# ESP32-C61 register map
Vendor: ESPRESSIF SYSTEMS (SHANGHAI) CO., LTD.; Series: ESP32 C-Series; File version: 1
CPU: RV32IMAC r0p0, little endian, no MPU, no FPU, 0 interrupt priority bits
Address unit: 32 bits
Registers are 32-bit, read-write, reset 0x0 unless marked. A register's access mark holds for its fields unless they carry their own. Offsets are from the block's base; [hi:lo] are bit positions; {n}, {i} and the like mark numbered series.

## INTERRUPT_CORE0 — Interrupt Controller (Core 0)
Base 0x60010000
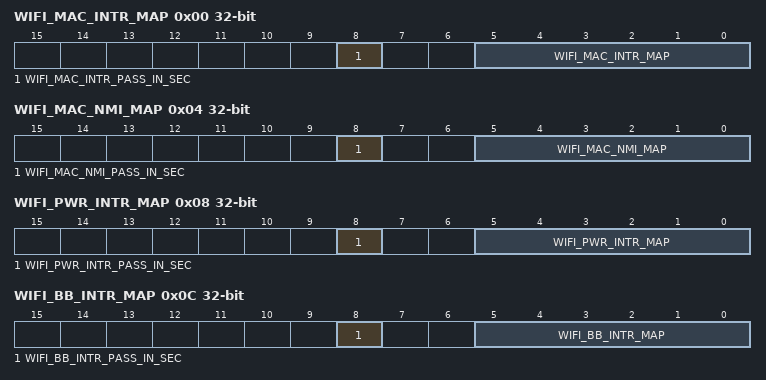
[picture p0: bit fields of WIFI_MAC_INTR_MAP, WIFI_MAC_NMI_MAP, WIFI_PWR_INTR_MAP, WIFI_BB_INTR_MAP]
0x00 WIFI_MAC_INTR_MAP — WIFI_MAC_INTR mapping register
  [8] WIFI_MAC_INTR_PASS_IN_SEC — Configures the PASS_IN_SEC flag of the interrupt source.
  [5:0] WIFI_MAC_INTR_MAP — Configures the interrupt source into one CPU interrupt.
0x04 WIFI_MAC_NMI_MAP — WIFI_MAC_NMI mapping register
  [8] WIFI_MAC_NMI_PASS_IN_SEC — Configures the PASS_IN_SEC flag of the interrupt source.
  [5:0] WIFI_MAC_NMI_MAP — Configures the interrupt source into one CPU interrupt.
0x08 WIFI_PWR_INTR_MAP — WIFI_PWR_INTR mapping register
  [8] WIFI_PWR_INTR_PASS_IN_SEC — Configures the PASS_IN_SEC flag of the interrupt source.
  [5:0] WIFI_PWR_INTR_MAP — Configures the interrupt source into one CPU interrupt.
0x0C WIFI_BB_INTR_MAP — WIFI_BB_INTR mapping register
  [8] WIFI_BB_INTR_PASS_IN_SEC — Configures the PASS_IN_SEC flag of the interrupt source.
  [5:0] WIFI_BB_INTR_MAP — Configures the interrupt source into one CPU interrupt.
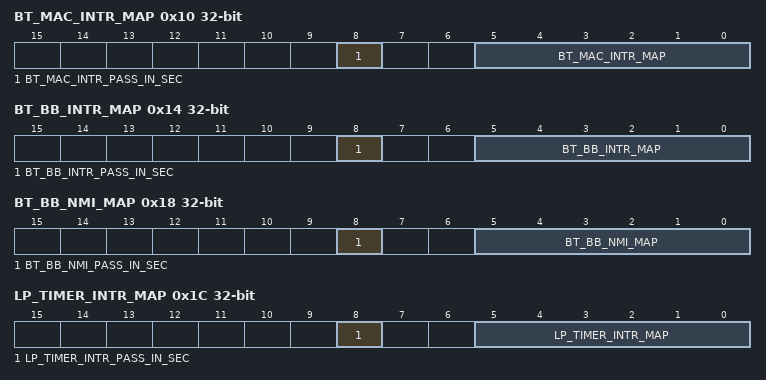
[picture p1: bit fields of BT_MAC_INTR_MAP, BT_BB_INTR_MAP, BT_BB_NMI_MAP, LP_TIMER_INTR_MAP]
0x10 BT_MAC_INTR_MAP — BT_MAC_INTR mapping register
  [8] BT_MAC_INTR_PASS_IN_SEC — Configures the PASS_IN_SEC flag of the interrupt source.
  [5:0] BT_MAC_INTR_MAP — Configures the interrupt source into one CPU interrupt.
0x14 BT_BB_INTR_MAP — BT_BB_INTR mapping register
  [8] BT_BB_INTR_PASS_IN_SEC — Configures the PASS_IN_SEC flag of the interrupt source.
  [5:0] BT_BB_INTR_MAP — Configures the interrupt source into one CPU interrupt.
0x18 BT_BB_NMI_MAP — BT_BB_NMI mapping register
  [8] BT_BB_NMI_PASS_IN_SEC — Configures the PASS_IN_SEC flag of the interrupt source.
  [5:0] BT_BB_NMI_MAP — Configures the interrupt source into one CPU interrupt.
0x1C LP_TIMER_INTR_MAP — LP_TIMER_INTR mapping register
  [8] LP_TIMER_INTR_PASS_IN_SEC — Configures the PASS_IN_SEC flag of the interrupt source.
  [5:0] LP_TIMER_INTR_MAP — Configures the interrupt source into one CPU interrupt.
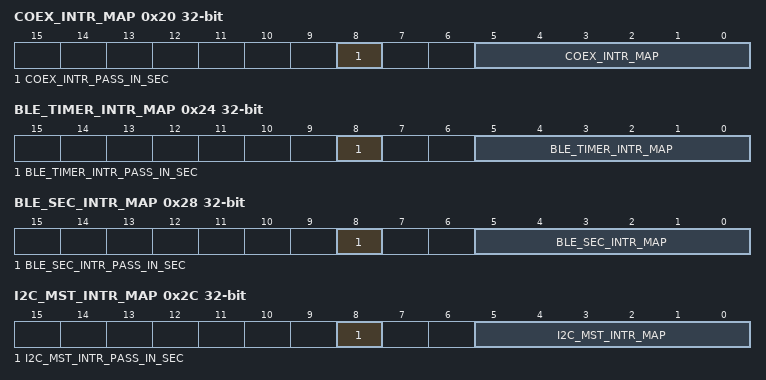
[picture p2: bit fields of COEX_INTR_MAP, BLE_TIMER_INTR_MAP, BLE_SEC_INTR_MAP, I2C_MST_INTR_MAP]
0x20 COEX_INTR_MAP — COEX_INTR mapping register
  [8] COEX_INTR_PASS_IN_SEC — Configures the PASS_IN_SEC flag of the interrupt source.
  [5:0] COEX_INTR_MAP — Configures the interrupt source into one CPU interrupt.
0x24 BLE_TIMER_INTR_MAP — BLE_TIMER_INTR mapping register
  [8] BLE_TIMER_INTR_PASS_IN_SEC — Configures the PASS_IN_SEC flag of the interrupt source.
  [5:0] BLE_TIMER_INTR_MAP — Configures the interrupt source into one CPU interrupt.
0x28 BLE_SEC_INTR_MAP — BLE_SEC_INTR mapping register
  [8] BLE_SEC_INTR_PASS_IN_SEC — Configures the PASS_IN_SEC flag of the interrupt source.
  [5:0] BLE_SEC_INTR_MAP — Configures the interrupt source into one CPU interrupt.
0x2C I2C_MST_INTR_MAP — I2C_MST_INTR mapping register
  [8] I2C_MST_INTR_PASS_IN_SEC — Configures the PASS_IN_SEC flag of the interrupt source.
  [5:0] I2C_MST_INTR_MAP — Configures the interrupt source into one CPU interrupt.
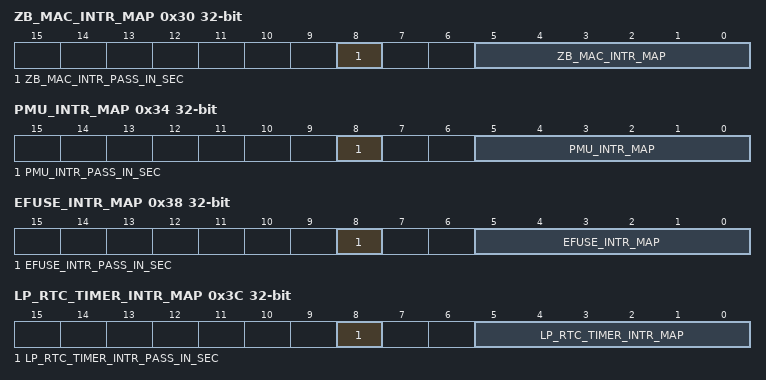
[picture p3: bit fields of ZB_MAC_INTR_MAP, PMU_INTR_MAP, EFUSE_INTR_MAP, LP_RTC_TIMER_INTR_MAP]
0x30 ZB_MAC_INTR_MAP — ZB_MAC_INTR mapping register
  [8] ZB_MAC_INTR_PASS_IN_SEC — Configures the PASS_IN_SEC flag of the interrupt source.
  [5:0] ZB_MAC_INTR_MAP — Configures the interrupt source into one CPU interrupt.
0x34 PMU_INTR_MAP — PMU_INTR mapping register
  [8] PMU_INTR_PASS_IN_SEC — Configures the PASS_IN_SEC flag of the interrupt source.
  [5:0] PMU_INTR_MAP — Configures the interrupt source into one CPU interrupt.
0x38 EFUSE_INTR_MAP — EFUSE_INTR mapping register
  [8] EFUSE_INTR_PASS_IN_SEC — Configures the PASS_IN_SEC flag of the interrupt source.
  [5:0] EFUSE_INTR_MAP — Configures the interrupt source into one CPU interrupt.
0x3C LP_RTC_TIMER_INTR_MAP — LP_RTC_TIMER_INTR mapping register
  [8] LP_RTC_TIMER_INTR_PASS_IN_SEC — Configures the PASS_IN_SEC flag of the interrupt source.
  [5:0] LP_RTC_TIMER_INTR_MAP — Configures the interrupt source into one CPU interrupt.
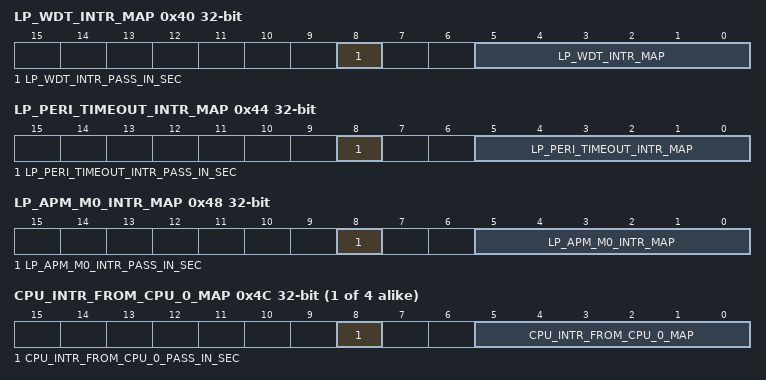
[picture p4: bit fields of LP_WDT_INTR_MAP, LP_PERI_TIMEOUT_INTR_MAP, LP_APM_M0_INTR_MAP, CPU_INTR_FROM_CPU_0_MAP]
0x40 LP_WDT_INTR_MAP — LP_WDT_INTR mapping register
  [8] LP_WDT_INTR_PASS_IN_SEC — Configures the PASS_IN_SEC flag of the interrupt source.
  [5:0] LP_WDT_INTR_MAP — Configures the interrupt source into one CPU interrupt.
0x44 LP_PERI_TIMEOUT_INTR_MAP — LP_PERI_TIMEOUT_INTR mapping register
  [8] LP_PERI_TIMEOUT_INTR_PASS_IN_SEC — Configures the PASS_IN_SEC flag of the interrupt source.
  [5:0] LP_PERI_TIMEOUT_INTR_MAP — Configures the interrupt source into one CPU interrupt.
0x48 LP_APM_M0_INTR_MAP — LP_APM_M0_INTR mapping register
  [8] LP_APM_M0_INTR_PASS_IN_SEC — Configures the PASS_IN_SEC flag of the interrupt source.
  [5:0] LP_APM_M0_INTR_MAP — Configures the interrupt source into one CPU interrupt.
{0x4C+4i} CPU_INTR_FROM_CPU_{i}_MAP (i=0..3) — CPU_INTR_FROM_CPU_{i} mapping register
  [8] CPU_INTR_FROM_CPU_{i}_PASS_IN_SEC — Configures the PASS_IN_SEC flag of the interrupt source.
  [5:0] CPU_INTR_FROM_CPU_{i}_MAP — Configures the interrupt source into one CPU interrupt.
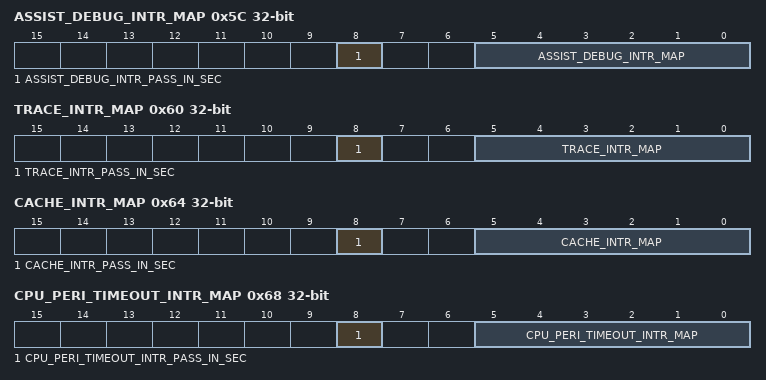
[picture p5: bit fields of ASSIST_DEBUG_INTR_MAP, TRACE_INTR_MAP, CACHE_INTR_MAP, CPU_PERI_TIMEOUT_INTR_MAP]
0x5C ASSIST_DEBUG_INTR_MAP — ASSIST_DEBUG_INTR mapping register
  [8] ASSIST_DEBUG_INTR_PASS_IN_SEC — Configures the PASS_IN_SEC flag of the interrupt source.
  [5:0] ASSIST_DEBUG_INTR_MAP — Configures the interrupt source into one CPU interrupt.
0x60 TRACE_INTR_MAP — TRACE_INTR mapping register
  [8] TRACE_INTR_PASS_IN_SEC — Configures the PASS_IN_SEC flag of the interrupt source.
  [5:0] TRACE_INTR_MAP — Configures the interrupt source into one CPU interrupt.
0x64 CACHE_INTR_MAP — CACHE_INTR mapping register
  [8] CACHE_INTR_PASS_IN_SEC — Configures the PASS_IN_SEC flag of the interrupt source.
  [5:0] CACHE_INTR_MAP — Configures the interrupt source into one CPU interrupt.
0x68 CPU_PERI_TIMEOUT_INTR_MAP — CPU_PERI_TIMEOUT_INTR mapping register
  [8] CPU_PERI_TIMEOUT_INTR_PASS_IN_SEC — Configures the PASS_IN_SEC flag of the interrupt source.
  [5:0] CPU_PERI_TIMEOUT_INTR_MAP — Configures the interrupt source into one CPU interrupt.
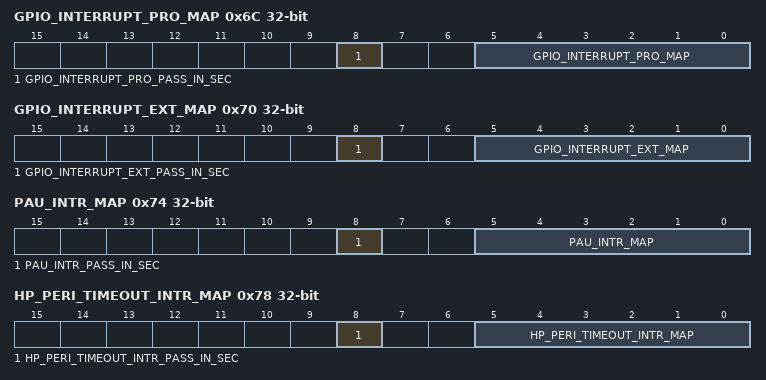
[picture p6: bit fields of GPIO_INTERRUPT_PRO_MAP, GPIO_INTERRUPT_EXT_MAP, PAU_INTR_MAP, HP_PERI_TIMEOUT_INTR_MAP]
0x6C GPIO_INTERRUPT_PRO_MAP — GPIO_INTERRUPT_PRO mapping register
  [8] GPIO_INTERRUPT_PRO_PASS_IN_SEC — Configures the PASS_IN_SEC flag of the interrupt source.
  [5:0] GPIO_INTERRUPT_PRO_MAP — Configures the interrupt source into one CPU interrupt.
0x70 GPIO_INTERRUPT_EXT_MAP — GPIO_INTERRUPT_EXT mapping register
  [8] GPIO_INTERRUPT_EXT_PASS_IN_SEC — Configures the PASS_IN_SEC flag of the interrupt source.
  [5:0] GPIO_INTERRUPT_EXT_MAP — Configures the interrupt source into one CPU interrupt.
0x74 PAU_INTR_MAP — PAU_INTR mapping register
  [8] PAU_INTR_PASS_IN_SEC — Configures the PASS_IN_SEC flag of the interrupt source.
  [5:0] PAU_INTR_MAP — Configures the interrupt source into one CPU interrupt.
0x78 HP_PERI_TIMEOUT_INTR_MAP — HP_PERI_TIMEOUT_INTR mapping register
  [8] HP_PERI_TIMEOUT_INTR_PASS_IN_SEC — Configures the PASS_IN_SEC flag of the interrupt source.
  [5:0] HP_PERI_TIMEOUT_INTR_MAP — Configures the interrupt source into one CPU interrupt.
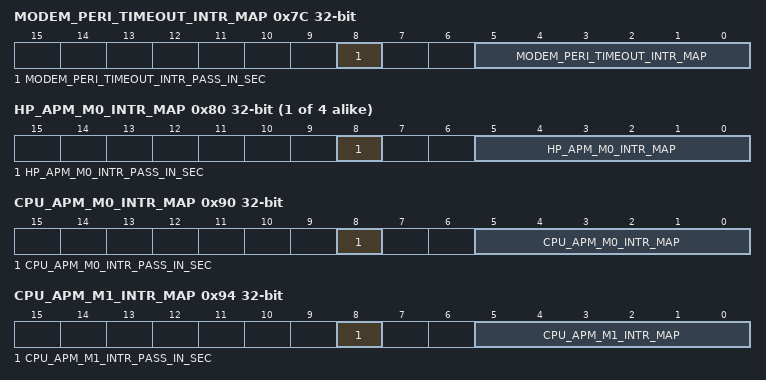
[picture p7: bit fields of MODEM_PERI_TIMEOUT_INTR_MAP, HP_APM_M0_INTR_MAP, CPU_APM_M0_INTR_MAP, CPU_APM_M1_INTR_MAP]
0x7C MODEM_PERI_TIMEOUT_INTR_MAP — MODEM_PERI_TIMEOUT_INTR mapping register
  [8] MODEM_PERI_TIMEOUT_INTR_PASS_IN_SEC — Configures the PASS_IN_SEC flag of the interrupt source.
  [5:0] MODEM_PERI_TIMEOUT_INTR_MAP — Configures the interrupt source into one CPU interrupt.
{0x80+4i} HP_APM_M{i}_INTR_MAP (i=0..3) — HP_APM_M{i}_INTR mapping register
  [8] HP_APM_M{i}_INTR_PASS_IN_SEC — Configures the PASS_IN_SEC flag of the interrupt source.
  [5:0] HP_APM_M{i}_INTR_MAP — Configures the interrupt source into one CPU interrupt.
0x90 CPU_APM_M0_INTR_MAP — CPU_APM_M0_INTR mapping register
  [8] CPU_APM_M0_INTR_PASS_IN_SEC — Configures the PASS_IN_SEC flag of the interrupt source.
  [5:0] CPU_APM_M0_INTR_MAP — Configures the interrupt source into one CPU interrupt.
0x94 CPU_APM_M1_INTR_MAP — CPU_APM_M1_INTR mapping register
  [8] CPU_APM_M1_INTR_PASS_IN_SEC — Configures the PASS_IN_SEC flag of the interrupt source.
  [5:0] CPU_APM_M1_INTR_MAP — Configures the interrupt source into one CPU interrupt.
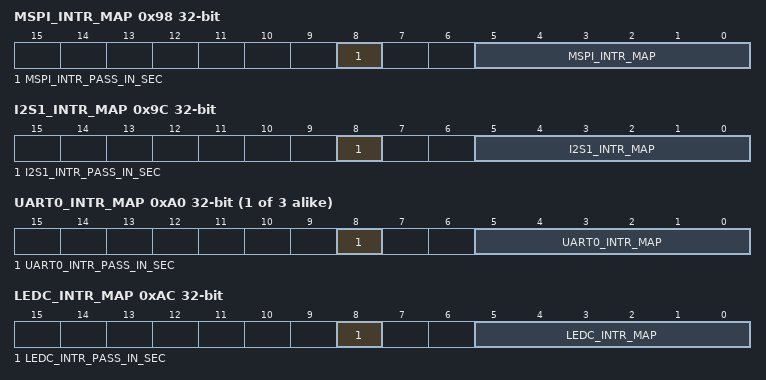
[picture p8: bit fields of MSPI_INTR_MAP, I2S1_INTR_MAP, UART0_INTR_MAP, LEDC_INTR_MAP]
0x98 MSPI_INTR_MAP — MSPI_INTR mapping register
  [8] MSPI_INTR_PASS_IN_SEC — Configures the PASS_IN_SEC flag of the interrupt source.
  [5:0] MSPI_INTR_MAP — Configures the interrupt source into one CPU interrupt.
0x9C I2S1_INTR_MAP — I2S1_INTR mapping register
  [8] I2S1_INTR_PASS_IN_SEC — Configures the PASS_IN_SEC flag of the interrupt source.
  [5:0] I2S1_INTR_MAP — Configures the interrupt source into one CPU interrupt.
{0xA0+4i} UART{i}_INTR_MAP (i=0..2) — UART{i}_INTR mapping register
  [8] UART{i}_INTR_PASS_IN_SEC — Configures the PASS_IN_SEC flag of the interrupt source.
  [5:0] UART{i}_INTR_MAP — Configures the interrupt source into one CPU interrupt.
0xAC LEDC_INTR_MAP — LEDC_INTR mapping register
  [8] LEDC_INTR_PASS_IN_SEC — Configures the PASS_IN_SEC flag of the interrupt source.
  [5:0] LEDC_INTR_MAP — Configures the interrupt source into one CPU interrupt.
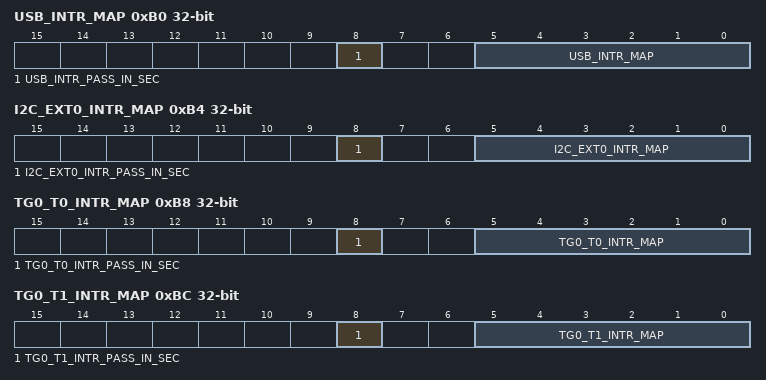
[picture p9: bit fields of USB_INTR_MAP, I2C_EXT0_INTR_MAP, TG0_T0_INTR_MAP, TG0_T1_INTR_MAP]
0xB0 USB_INTR_MAP — USB_INTR mapping register
  [8] USB_INTR_PASS_IN_SEC — Configures the PASS_IN_SEC flag of the interrupt source.
  [5:0] USB_INTR_MAP — Configures the interrupt source into one CPU interrupt.
0xB4 I2C_EXT0_INTR_MAP — I2C_EXT0_INTR mapping register
  [8] I2C_EXT0_INTR_PASS_IN_SEC — Configures the PASS_IN_SEC flag of the interrupt source.
  [5:0] I2C_EXT0_INTR_MAP — Configures the interrupt source into one CPU interrupt.
0xB8 TG0_T0_INTR_MAP — TG0_T0_INTR mapping register
  [8] TG0_T0_INTR_PASS_IN_SEC — Configures the PASS_IN_SEC flag of the interrupt source.
  [5:0] TG0_T0_INTR_MAP — Configures the interrupt source into one CPU interrupt.
0xBC TG0_T1_INTR_MAP — TG0_T1_INTR mapping register
  [8] TG0_T1_INTR_PASS_IN_SEC — Configures the PASS_IN_SEC flag of the interrupt source.
  [5:0] TG0_T1_INTR_MAP — Configures the interrupt source into one CPU interrupt.
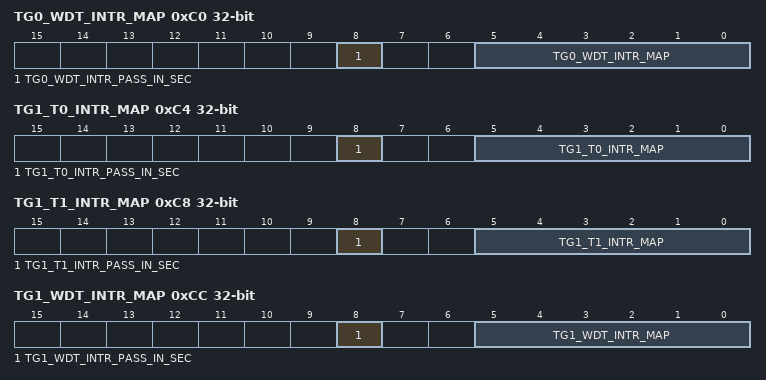
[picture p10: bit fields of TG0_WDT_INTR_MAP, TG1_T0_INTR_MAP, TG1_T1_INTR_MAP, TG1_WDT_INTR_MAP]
0xC0 TG0_WDT_INTR_MAP — TG0_WDT_INTR mapping register
  [8] TG0_WDT_INTR_PASS_IN_SEC — Configures the PASS_IN_SEC flag of the interrupt source.
  [5:0] TG0_WDT_INTR_MAP — Configures the interrupt source into one CPU interrupt.
0xC4 TG1_T0_INTR_MAP — TG1_T0_INTR mapping register
  [8] TG1_T0_INTR_PASS_IN_SEC — Configures the PASS_IN_SEC flag of the interrupt source.
  [5:0] TG1_T0_INTR_MAP — Configures the interrupt source into one CPU interrupt.
0xC8 TG1_T1_INTR_MAP — TG1_T1_INTR mapping register
  [8] TG1_T1_INTR_PASS_IN_SEC — Configures the PASS_IN_SEC flag of the interrupt source.
  [5:0] TG1_T1_INTR_MAP — Configures the interrupt source into one CPU interrupt.
0xCC TG1_WDT_INTR_MAP — TG1_WDT_INTR mapping register
  [8] TG1_WDT_INTR_PASS_IN_SEC — Configures the PASS_IN_SEC flag of the interrupt source.
  [5:0] TG1_WDT_INTR_MAP — Configures the interrupt source into one CPU interrupt.
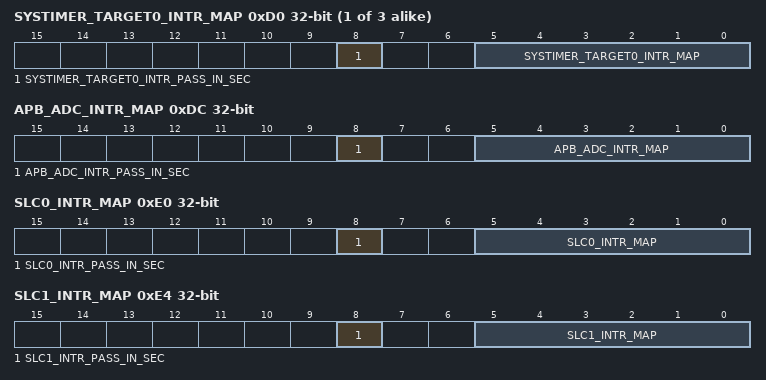
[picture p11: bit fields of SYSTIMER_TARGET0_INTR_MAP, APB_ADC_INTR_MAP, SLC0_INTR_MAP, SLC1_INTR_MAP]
{0xD0+4i} SYSTIMER_TARGET{i}_INTR_MAP (i=0..2) — SYSTIMER_TARGET{i}_INTR mapping register
  [8] SYSTIMER_TARGET{i}_INTR_PASS_IN_SEC — Configures the PASS_IN_SEC flag of the interrupt source.
  [5:0] SYSTIMER_TARGET{i}_INTR_MAP — Configures the interrupt source into one CPU interrupt.
0xDC APB_ADC_INTR_MAP — APB_ADC_INTR mapping register
  [8] APB_ADC_INTR_PASS_IN_SEC — Configures the PASS_IN_SEC flag of the interrupt source.
  [5:0] APB_ADC_INTR_MAP — Configures the interrupt source into one CPU interrupt.
0xE0 SLC0_INTR_MAP — SLC0_INTR mapping register
  [8] SLC0_INTR_PASS_IN_SEC — Configures the PASS_IN_SEC flag of the interrupt source.
  [5:0] SLC0_INTR_MAP — Configures the interrupt source into one CPU interrupt.
0xE4 SLC1_INTR_MAP — SLC1_INTR mapping register
  [8] SLC1_INTR_PASS_IN_SEC — Configures the PASS_IN_SEC flag of the interrupt source.
  [5:0] SLC1_INTR_MAP — Configures the interrupt source into one CPU interrupt.
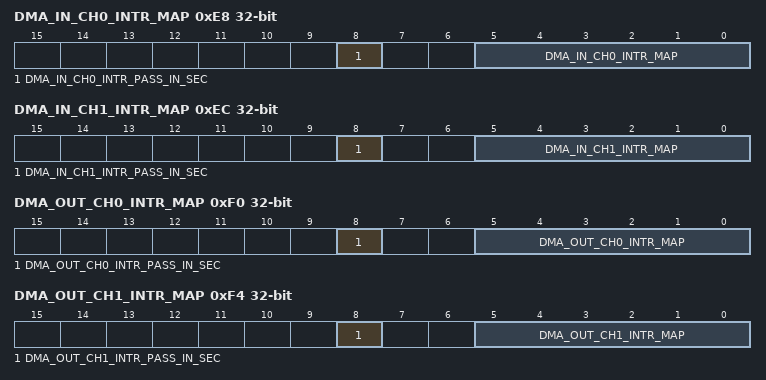
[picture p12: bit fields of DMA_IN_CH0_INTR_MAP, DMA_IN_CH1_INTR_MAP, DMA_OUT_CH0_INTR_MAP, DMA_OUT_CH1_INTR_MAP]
0xE8 DMA_IN_CH0_INTR_MAP — DMA_IN_CH0_INTR mapping register
  [8] DMA_IN_CH0_INTR_PASS_IN_SEC — Configures the PASS_IN_SEC flag of the interrupt source.
  [5:0] DMA_IN_CH0_INTR_MAP — Configures the interrupt source into one CPU interrupt.
0xEC DMA_IN_CH1_INTR_MAP — DMA_IN_CH1_INTR mapping register
  [8] DMA_IN_CH1_INTR_PASS_IN_SEC — Configures the PASS_IN_SEC flag of the interrupt source.
  [5:0] DMA_IN_CH1_INTR_MAP — Configures the interrupt source into one CPU interrupt.
0xF0 DMA_OUT_CH0_INTR_MAP — DMA_OUT_CH0_INTR mapping register
  [8] DMA_OUT_CH0_INTR_PASS_IN_SEC — Configures the PASS_IN_SEC flag of the interrupt source.
  [5:0] DMA_OUT_CH0_INTR_MAP — Configures the interrupt source into one CPU interrupt.
0xF4 DMA_OUT_CH1_INTR_MAP — DMA_OUT_CH1_INTR mapping register
  [8] DMA_OUT_CH1_INTR_PASS_IN_SEC — Configures the PASS_IN_SEC flag of the interrupt source.
  [5:0] DMA_OUT_CH1_INTR_MAP — Configures the interrupt source into one CPU interrupt.
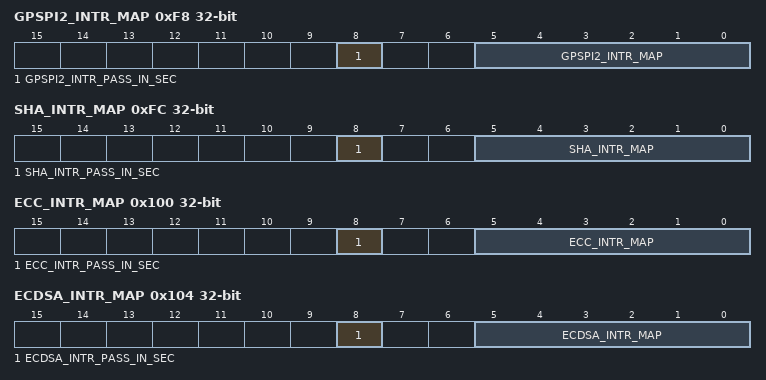
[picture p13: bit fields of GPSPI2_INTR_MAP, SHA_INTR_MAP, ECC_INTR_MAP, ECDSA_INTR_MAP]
0xF8 GPSPI2_INTR_MAP — GPSPI2_INTR mapping register
  [8] GPSPI2_INTR_PASS_IN_SEC — Configures the PASS_IN_SEC flag of the interrupt source.
  [5:0] GPSPI2_INTR_MAP — Configures the interrupt source into one CPU interrupt.
0xFC SHA_INTR_MAP — SHA_INTR mapping register
  [8] SHA_INTR_PASS_IN_SEC — Configures the PASS_IN_SEC flag of the interrupt source.
  [5:0] SHA_INTR_MAP — Configures the interrupt source into one CPU interrupt.
0x100 ECC_INTR_MAP — ECC_INTR mapping register
  [8] ECC_INTR_PASS_IN_SEC — Configures the PASS_IN_SEC flag of the interrupt source.
  [5:0] ECC_INTR_MAP — Configures the interrupt source into one CPU interrupt.
0x104 ECDSA_INTR_MAP — ECDSA_INTR mapping register
  [8] ECDSA_INTR_PASS_IN_SEC — Configures the PASS_IN_SEC flag of the interrupt source.
  [5:0] ECDSA_INTR_MAP — Configures the interrupt source into one CPU interrupt.
0x108 INT_STATUS_REG_0 ro — Status register for interrupt sources 0 ~ 31
  [31:0] INT_STATUS_0 — Represents the status of the interrupt sources within interrupt-index-range 0 ~ 31. Each bit corresponds to one interrupt source 0:The corresponding interrupt source triggered an interrupt 1:No interrupt triggered
0x10C INT_STATUS_REG_1 ro — Status register for interrupt sources 32 ~ 63
  [31:0] INT_STATUS_1 — Represents the status of the interrupt sources within interrupt-index-range 32 ~ 63. Each bit corresponds to one interrupt source 0:The corresponding interrupt source triggered an interrupt 1:No interrupt triggered
0x110 INT_STATUS_REG_2 ro — Status register for interrupt sources 64 ~ 65
  [1:0] INT_STATUS_2 — Represents the status of the interrupt sources within interrupt-index-range 64 ~ 65. Each bit corresponds to one interrupt source 0:The corresponding interrupt source triggered an interrupt 1:No interrupt triggered
0x114 SRC_PASS_IN_SEC_STATUS_0 ro — PASS_IN_SEC status register for interrupt sources 0 ~ 31
  [31:0] INT_SRC_PASS_IN_SEC_STATUS_0 — Represents the PASS_IN_SEC status of the interrupt sources within interrupt-index-range 0 ~ 31. Each bit corresponds to one interrupt source 0:The corresponding interrupt source is not PASS_IN_SEC. 1:The corresponding interrupt source is PASS_IN_SEC.
0x118 SRC_PASS_IN_SEC_STATUS_1 ro — PASS_IN_SEC status register for interrupt sources 32 ~ 63
  [31:0] INT_SRC_PASS_IN_SEC_STATUS_1 — Represents the PASS_IN_SEC status of the interrupt sources within interrupt-index-range 32 ~ 63. Each bit corresponds to one interrupt source 0:The corresponding interrupt source is not PASS_IN_SEC. 1:The corresponding interrupt source is PASS_IN_SEC.
0x11C SRC_PASS_IN_SEC_STATUS_2 ro — PASS_IN_SEC status register for interrupt sources 64 ~ 65
  [1:0] INT_SRC_PASS_IN_SEC_STATUS_2 — Represents the PASS_IN_SEC status of the interrupt sources with interrupt-index-range 64 ~ 65. Each bit corresponds to one interrupt source 0:The corresponding interrupt source is not PASS_IN_SEC. 1:The corresponding interrupt source is PASS_IN_SEC.
0x120 SIG_IDX_ASSERT_IN_SEC — reserved
  [5:0] INT_SIG_IDX_ASSERT_IN_SEC
0x124 SECURE_STATUS ro — reserved
  [31:0] INT_SECURE_STATUS
0x128 CLOCK_GATE — Interrupt clock gating configure register
  [0] REG_CLK_EN
0x7FC INTERRUPT_DATE reset 0x2501021 — Version control register
  [27:0] INTERRUPT_DATE
